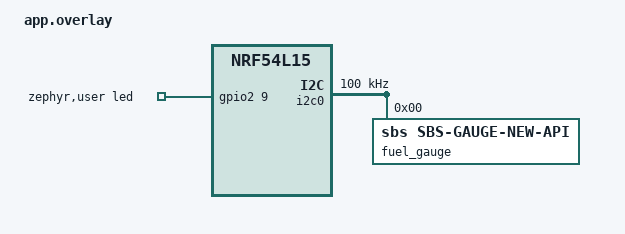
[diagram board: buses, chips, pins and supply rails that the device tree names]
/ {
    chosen {
        // We use shell's backend for logging, so disable the console backend
        /delete-property/ zephyr,console;

        zephyr,shell-uart = &uart20;
    };

    zephyr,user {
        led-gpios = <&gpio2 9 GPIO_ACTIVE_HIGH>;
    };

    soc {

    }; /* soc */

    #include "../nrf54l15_fstab.dtsi"

    i2c0: i2c@0 {
        status = "okay";
        compatible = "zephyr,i2c-emul-controller";
        clock-frequency = <I2C_BITRATE_STANDARD>;
        #address-cells = <1>;
        #size-cells = <0>;
        reg = <0x0 4>;

        /* Simulated device; will talk to projects/zephyr/drivers/fuel_gauge/sbs_gauge/emul_sbs_gauge.c */
        fuel_gauge: fuel_gauge@0 {
            compatible = "sbs,sbs-gauge-new-api";
            status = "okay";
            reg = <0x0>;
        };
    };

}; /* root */

&cpuapp_rram {
    /delete-node/ partitions;
    #include "../nrf54l15_partitions.dtsi"
};

&gpio2 {
    status = "okay";
};
